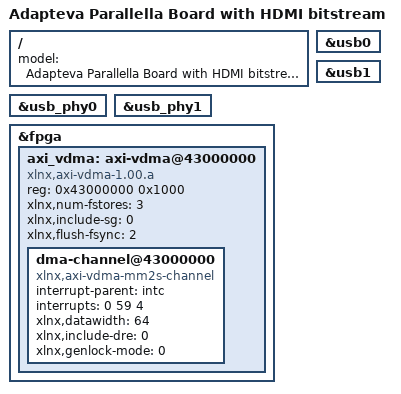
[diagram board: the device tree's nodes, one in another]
/*
 * Copyright (c) 2014 SUSE LINUX Products GmbH
 * Copyright (c) 2015 SUSE Linux GmbH
 *
 * This software is licensed under the terms of the GNU General Public
 * License version 2, as published by the Free Software Foundation, and
 * may be copied, distributed, and modified under those terms.
 *
 * This program is distributed in the hope that it will be useful,
 * but WITHOUT ANY WARRANTY; without even the implied warranty of
 * MERCHANTABILITY or FITNESS FOR A PARTICULAR PURPOSE.  See the
 * GNU General Public License for more details.
 */
/dts-v1/;
#include "zynq-parallella1.dtsi"

/ {
	model = "Adapteva Parallella Board with HDMI bitstream";
};

&usb_phy0 {
	status = "okay";
};

&usb_phy1 {
	status = "okay";
};

&fpga {
	axi_vdma: axi-vdma@43000000 {
		compatible = "xlnx,axi-vdma-1.00.a";
		reg = <0x43000000 0x1000>;
		#dma-cells = <1>;
		xlnx,num-fstores = <3>;
		xlnx,include-sg = <0>;
		xlnx,flush-fsync = <2>;

		dma-channel@43000000 {
			compatible = "xlnx,axi-vdma-mm2s-channel";
			interrupt-parent = <&intc>;
			interrupts = <0 59 4>;
			xlnx,datawidth = <64>;
			xlnx,include-dre = <0>;
			xlnx,genlock-mode = <0>;
		};
	};
};

&usb0 {
	status = "okay";
};

&usb1 {
	status = "okay";
};
